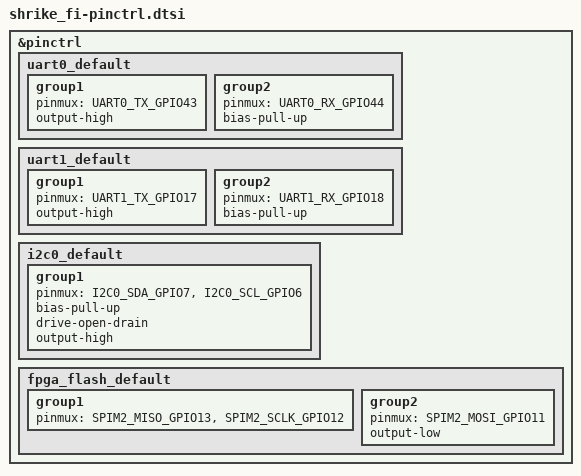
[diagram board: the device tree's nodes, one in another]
/*
 * Copyright (C) 2026 Dhruv Menon <dhruvmenon1104@gmail.com>
 * SPDX-License-Identifier: Apache-2.0
 */

#include <zephyr/dt-bindings/pinctrl/esp32s3-pinctrl.h>

&pinctrl {
	uart0_default: uart0_default {
		group1 {
			pinmux = <UART0_TX_GPIO43>;
			output-high;
		};

		group2 {
			pinmux = <UART0_RX_GPIO44>;
			bias-pull-up;
		};
	};

	uart1_default: uart1_default {
		group1 {
			pinmux = <UART1_TX_GPIO17>;
			output-high;
		};

		group2 {
			pinmux = <UART1_RX_GPIO18>;
			bias-pull-up;
		};
	};

	i2c0_default: i2c0_default {
		group1 {
			pinmux = <I2C0_SDA_GPIO7>,
				 <I2C0_SCL_GPIO6>;
			bias-pull-up;
			drive-open-drain;
			output-high;
		};
	};

	/* FPGA configuration / MCU-FPGA link: SCLK=12, MOSI=11, MISO=13.
	 * SS (GPIO10) is driven as a GPIO via ss-gpios, not hardware CS.
	 */
	fpga_flash_default: fpga_flash_default {
		group1 {
			pinmux = <SPIM2_MISO_GPIO13>,
				 <SPIM2_SCLK_GPIO12>;
		};

		group2 {
			pinmux = <SPIM2_MOSI_GPIO11>;
			output-low;
		};
	};
};
